NS_ :

BS_:

BU_: Receiver ChassisBus VehicleBus PartyBus
VAL_TABLE_ New_Value_Table_931 2 "qqq" 1 "test" ;

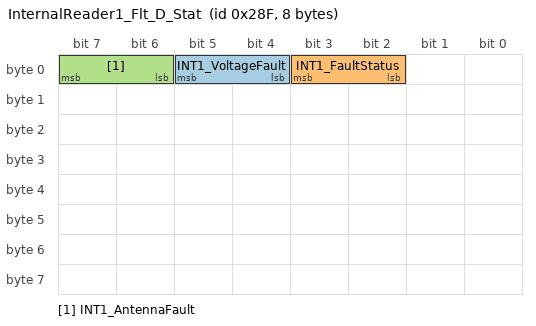
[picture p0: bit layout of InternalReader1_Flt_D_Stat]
BO_ 655 InternalReader1_Flt_D_Stat: 8 NFCR_INT_1
SG_ INT1_VoltageFault : 5|2@0+ (1,0) [0|3] "" RFA_BUNSG
SG_ INT1_FaultStatus : 3|2@0+( 1,0) [0|3] "" RFA_BUN
SG_ INT1_AntennaFault : 7|2@0+ (1,0) [0|3] "" RFA_BUN

BO_TX_BU_ 1638 : RFA_BUN,TSTR;

BA_DEF_DEF_  "ReleaseVersionNumber" "V0.30.0";
